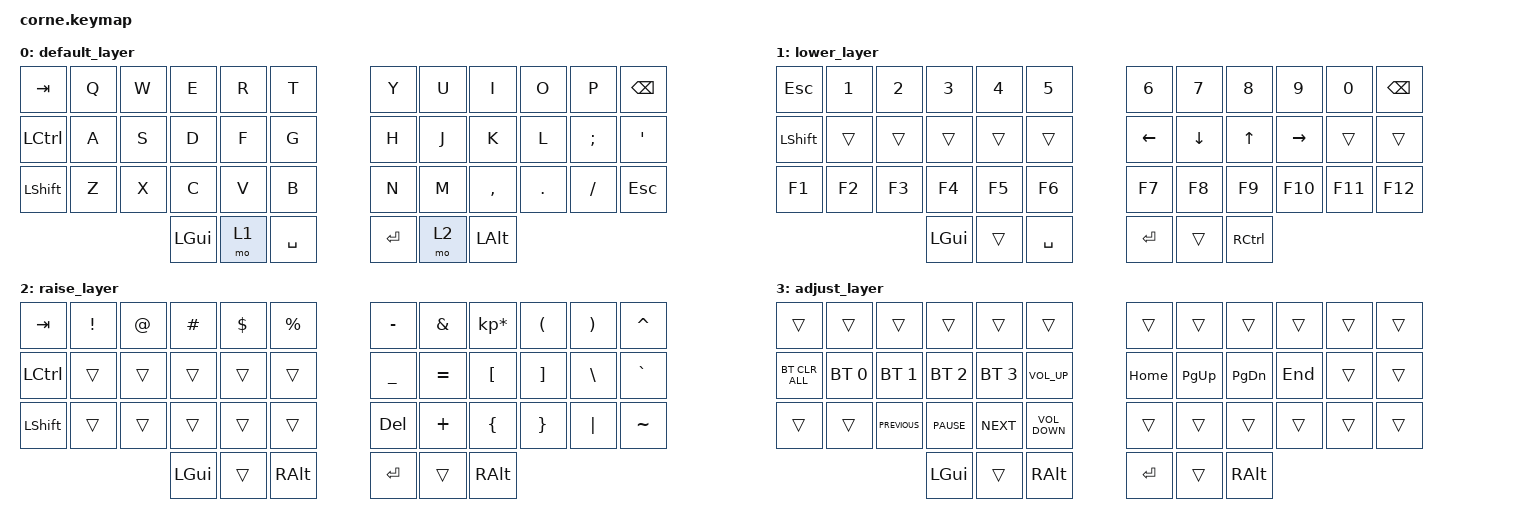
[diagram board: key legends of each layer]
/*
 * Copyright (c) 2020 The ZMK Contributors
 *
 * SPDX-License-Identifier: MIT
 */

#include <behaviors.dtsi>
#include <dt-bindings/zmk/keys.h>
#include <dt-bindings/zmk/bt.h>

 / {
    conditional_layers {
        compatible = "zmk,conditional-layers";
        tri_layer {
            if-layers = <1 2>;
            then-layer = <3>;
        };
    };
    keymap {
        compatible = "zmk,keymap";

        default_layer {
            bindings = <
                &kp TAB   &kp Q &kp W &kp E &kp R &kp T   &kp Y &kp U  &kp I     &kp O   &kp P    &kp BSPC
                &kp LCTRL &kp A &kp S &kp D &kp F &kp G   &kp H &kp J  &kp K     &kp L   &kp SEMI &kp SQT
                &kp LSHFT &kp Z &kp X &kp C &kp V &kp B   &kp N &kp M  &kp COMMA &kp DOT &kp FSLH &kp ESC
                &kp LGUI &mo 1 &kp SPACE   &kp RET &mo 2 &kp LALT
            >;
        };

        lower_layer {
            bindings = <
                &kp ESC &kp N1 &kp N2 &kp N3 &kp N4 &kp N5   &kp N6 &kp N7 &kp N8 &kp N9 &kp N0 &kp BSPC
                &kp LSHFT  &trans &trans &trans &trans &trans &kp LEFT &kp DOWN &kp UP &kp RIGHT &trans &trans
                &kp F1 &kp F2 &kp F3 &kp F4 &kp F5 &kp F6   &kp F7 &kp F8 &kp F9 &kp F10 &kp F11 &kp F12
                &kp LGUI &trans &kp SPACE &kp RET &trans &kp RCTRL
            >;
        };

        raise_layer {
            bindings = <
                &kp TAB  &kp EXCL &kp AT &kp HASH &kp DLLR &kp PRCNT   &kp MINUS  &kp AMPS &kp KP_MULTIPLY &kp LPAR &kp RPAR &kp CARET
                &kp LCTRL &trans &trans &trans &trans &trans &kp UNDER &kp EQUAL &kp LBKT &kp RBKT &kp BSLH &kp GRAVE
                &kp LSHFT &trans &trans&trans &trans &trans &kp DEL &kp PLUS &kp LBRC &kp RBRC &kp PIPE &kp TILDE
                &kp LGUI &trans &kp RALT &kp RET &trans &kp RALT
            >;
        };

        adjust_layer {
            bindings = <
                &trans &trans &trans &trans &trans &trans &trans &trans &trans &trans &trans &trans
                &bt BT_CLR_ALL &bt BT_SEL 0 &bt BT_SEL 1 &bt BT_SEL 2 &bt BT_SEL 3 &kp C_VOLUME_UP &kp HOME &kp PG_UP &kp PG_DN &kp END &trans &trans
                &trans &trans &kp C_PREVIOUS &kp C_PAUSE &kp C_NEXT &kp C_VOLUME_DOWN &trans &trans &trans &trans &trans &trans
                &kp LGUI &trans &kp RALT &kp RET &trans &kp RALT
            >;
        };
    };
};

&led_strip {
    chain-length = <27>;
};
